VERSION ""

NS_ :

BS_:

BU_: XXX

BO_ 496 NEW_MSG_1: 8 XXX
 SG_ NEW_SIGNAL_1 : 0|8@1+ (1,0) [0|255] "" XXX

BO_ 809 NEW_MSG_2: 8 XXX

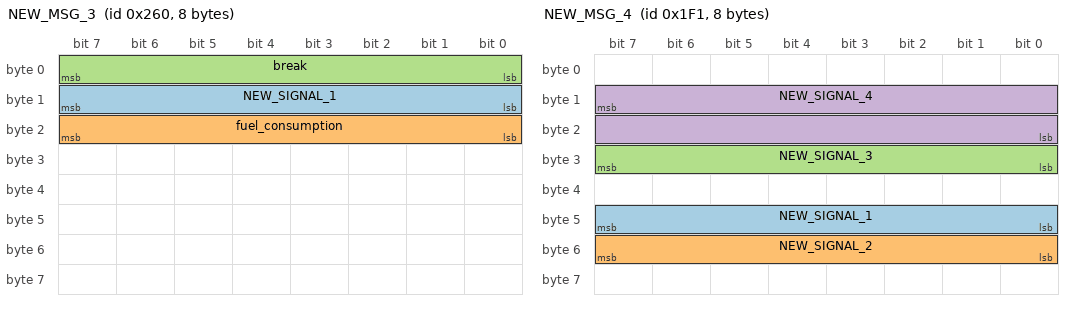
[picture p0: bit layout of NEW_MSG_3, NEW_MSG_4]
BO_ 608 NEW_MSG_3: 8 XXX
 SG_ NEW_SIGNAL_1 : 8|8@1+ (1,0) [0|255] "" XXX
 SG_ fuel_consumption : 23|8@0+ (1,0) [0|255] "" XXX
 SG_ break : 0|8@1+ (1,0) [0|255] "" XXX

BO_ 497 NEW_MSG_4: 8 XXX
 SG_ NEW_SIGNAL_1 : 47|8@0+ (1,0) [0|255] "" XXX
 SG_ NEW_SIGNAL_2 : 55|8@0+ (1,0) [0|255] "" XXX
 SG_ NEW_SIGNAL_3 : 31|8@0+ (1,0) [0|255] "" XXX
 SG_ NEW_SIGNAL_4 : 15|16@0+ (1,0) [0|255] "" XXX

BO_ 1087 NEW_MSG_5: 8 XXX
 SG_ NEW_SIGNAL_1 : 47|8@0+ (1,0) [0|255] "" XXX
